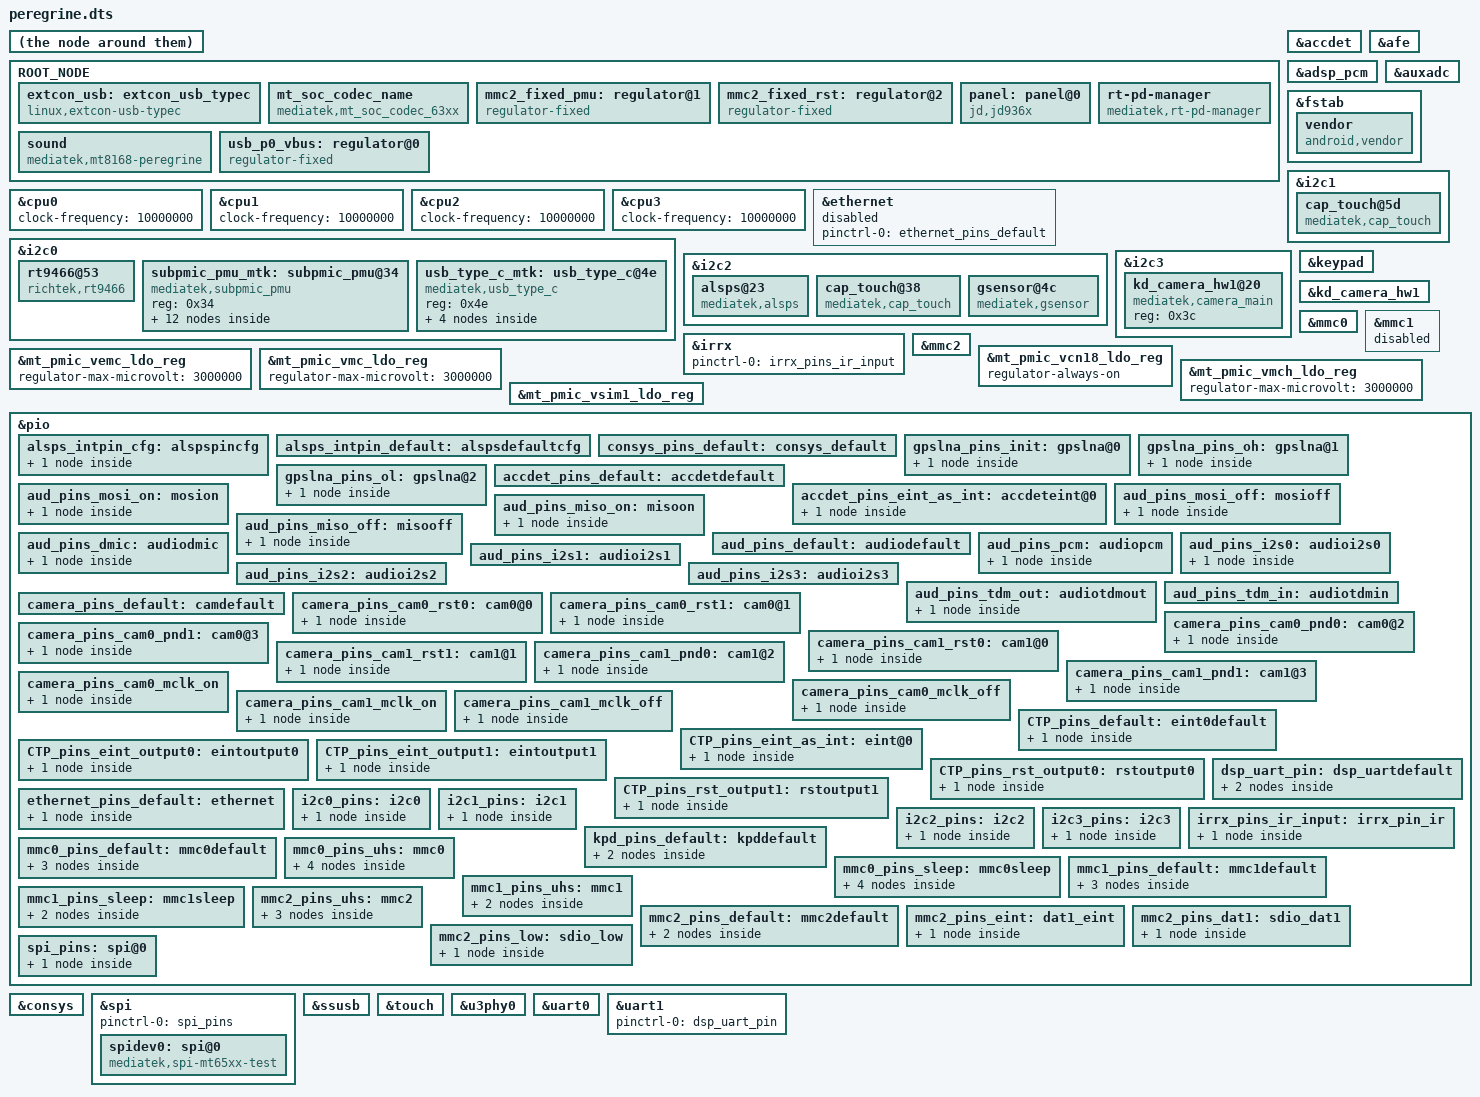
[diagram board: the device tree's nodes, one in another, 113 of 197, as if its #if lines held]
/*
 * Copyright (c) 2018 MediaTek Inc.
 *
 * This program is free software; you can redistribute it and/or modify
 * it under the terms of the GNU General Public License version 2 as
 * published by the Free Software Foundation.
 *
 * This program is distributed in the hope that it will be useful,
 * MERCHANTABILITY or FITNESS FOR A PARTICULAR PURPOSE.  See the
 * GNU General Public License for more details.
 */

#include <generated/autoconf.h>
/dts-v1/;

/plugin/;
#include <dt-bindings/clock/mt8168-clk.h>
#include <dt-bindings/interrupt-controller/irq.h>
#include <dt-bindings/interrupt-controller/arm-gic.h>
#include <dt-bindings/pinctrl/mt8168-pinfunc.h>
#include <dt-bindings/gpio/gpio.h>
#include <dt-bindings/phy/phy.h>
#define ROOT_NODE &odm

ROOT_NODE {
	extcon_usb: extcon_usb_typec {
		compatible = "linux,extcon-usb-typec";
	};

	mt_soc_codec_name: mt_soc_codec_name {
		compatible = "mediatek,mt_soc_codec_63xx";
		use_hp_depop_flow = <0>; /* select 1: use, 0: not use */
		use_ul_260k = <0>; /* select 1: use, 0: not use */
	};

	mmc2_fixed_pmu: regulator@1 {
		compatible = "regulator-fixed";
		regulator-name = "mmc2_pmu";
		regulator-min-microvolt = <3300000>;
		regulator-max-microvolt = <3300000>;
		gpio = <&pio 133 0>;
		enable-active-high;
	};

	mmc2_fixed_rst: regulator@2 {
		compatible = "regulator-fixed";
		regulator-name = "mmc2_rst";
		regulator-min-microvolt = <1800000>;
		regulator-max-microvolt = <1800000>;
		gpio = <&pio 143 0>;
		enable-active-high;
	};

	panel: panel@0 {
		compatible = "jd,jd936x";
		gpio_lcd_rst = <&pio 23 0>;
		gpio_bl_en = <&pio 79 0>;
	};

	rt-pd-manager {
		compatible = "mediatek,rt-pd-manager";
	};

	sound: sound {
		compatible = "mediatek,mt8168-peregrine";
		mediatek,platform = <&afe>;
		mediatek,adsp-platform = <&adsp_pcm>;
		pinctrl-names = "aud_mosi_on",
				"aud_mosi_off",
				"aud_miso_on",
				"aud_miso_off",
				"default",
				"aud_dmic",
				"aud_pcm",
				"aud_i2s0",
				"aud_i2s1",
				"aud_i2s2",
				"aud_i2s3",
				"aud_tdm_out",
				"aud_tdm_in";
		pinctrl-0 = <&aud_pins_mosi_on>;
		pinctrl-1 = <&aud_pins_mosi_off>;
		pinctrl-2 = <&aud_pins_miso_on>;
		pinctrl-3 = <&aud_pins_miso_off>;
		pinctrl-4 = <&aud_pins_default>;
		pinctrl-5 = <&aud_pins_dmic>;
		pinctrl-6 = <&aud_pins_pcm>;
		pinctrl-7 = <&aud_pins_i2s0>;
		pinctrl-8 = <&aud_pins_i2s1>;
		pinctrl-9 = <&aud_pins_i2s2>;
		pinctrl-10 = <&aud_pins_i2s3>;
		pinctrl-11 = <&aud_pins_tdm_out>;
		pinctrl-12 = <&aud_pins_tdm_in>;
		tab-spk-en-gpio = <&pio 3 0>;
		spkr-sel-gpio = <&pio 122 0>;
		mic-sel-gpio = <&pio 109 0>;
		status = "okay";
	};

	usb_p0_vbus: regulator@0 {
		compatible = "regulator-fixed";
		regulator-name = "vbus";
		regulator-min-microvolt = <5000000>;
		regulator-max-microvolt = <5000000>;
		gpio = <&pio 40 GPIO_ACTIVE_HIGH>;
		enable-active-high;
	};
};

&accdet {
	accdet-mic-vol = <6>;
	headset-mode-setting = <0x500 0x500 1 0x1f0 0x800 0x800 0x20 0x44>;
	accdet-plugout-debounce = <1>;
	accdet-mic-mode = <1>;
	headset-eint-level-pol = <8>;
	headset-three-key-threshold = <0 80 220 400>;
	headset-three-key-threshold-CDD = <0 121 192 600>;
	headset-four-key-threshold = <0 58 121 192 400>;
	pinctrl-names = "default", "state_eint_as_int";
	pinctrl-0 = <&accdet_pins_default>;
	pinctrl-1 = <&accdet_pins_eint_as_int>;
	status = "okay";
};

&afe {
	/* 0(I2S) 1(TDM) 2(I2S-32BITS) */
	mediatek,tdm-out-mode = <0>;
	/* 0(ONE_WIRE) 1(TWO_WIRE) */
	mediatek,dmic-two-wire-mode = <0>;
	/* 0(SEPARATE_CLK) 1(SHARE_CLK) */
	mediatek,i2s-clock-modes = <0 1>;
	status = "okay";
};

&adsp_pcm {
	status = "okay";
};

&auxadc {
	status = "okay";
};

&cpu0 {
	clock-frequency = <10000000>;
};

&cpu1 {
	clock-frequency = <10000000>;
};

&cpu2 {
	clock-frequency = <10000000>;
};

&cpu3 {
	clock-frequency = <10000000>;
};

&ethernet {
	status = "disabled";
	pinctrl-names = "default";
	pinctrl-0 = <&ethernet_pins_default>;
};

&fstab {
	vendor {
		compatible = "android,vendor";
		dev = "/dev/block/platform/soc/11230000.mmc/by-name/vendor";
		type = "ext4";
		mnt_flags = "ro";
		fsmgr_flags = "wait,verify";
	};
};

&i2c0 {
	pinctrl-names = "default";
	pinctrl-0 = <&i2c0_pins>;
	clock-frequency = <100000>;
	status = "okay";
	id = <0>;
	rt9466@53 {
		compatible = "richtek,rt9466";
		reg = <0x53>;
		/* rt,ceb_gpio_num = <160>; */
		interrupt-parent = <&pio>;
		interrupts = <124 IRQ_TYPE_EDGE_FALLING>;
		rt,intr_gpio = <&pio 10 0x0>;
		rt-interrupt-names = "wdtmri", "chg_mivr", "chg_aiclmeasi",
			"chg_statci", "chg_ieoci", "pwr_rdy";
		status = "okay";
		/*
		 * Charger name
		 * Main charger: primary_chg
		 * Slave charger: secondary_chg
		 */
		charger_name = "primary_chg";
		ichg = <2000000>; /* uA */
		aicr = <500000>;  /* uA */
		mivr = <4400000>; /* uV */
		cv = <4350000>;   /* uV */
		ieoc = <250000>;  /* uA */
		safety_timer = <12>;  /* hour */
		ircmp_resistor = <80000>; /* uohm */
		ircmp_vclamp = <96000>;  /* uV */
		en_te;
		/* en_wdt; */ /* remove it to support remote OTG wakeup */
		/* en_jeita; */
		/* en_irq_pulse; */
		/* ceb_invert; */
	};
	subpmic_pmu_mtk:subpmic_pmu@34 {
		compatible = "mediatek,subpmic_pmu";
		reg = <0x34>;
		status = "okay";
		mt6370_pmu: mt6370_pmu_dts {
			interrupt-controller;
			#interrupt-cells = <1>;
			interrupt-parent = <&pio>;
			interrupts = <12 IRQ_TYPE_EDGE_FALLING>;
			/* direct defined GPIO num */
			mt6370,intr_gpio_num = <12>;
			mt6370,intr_gpio = <&pio 12 0x0>; /* GPIO */
			core {
				compatible = "mediatek,mt6370_pmu_core";
				interrupt-names = "otp", "vdda_ovp", "vdda_uv";
				/* i2c safe timer reset function */
				//i2cstmr_rst_en;
				/* 0: 0.5s, 1: 0.75s, 2: 1s, 3: 2s */
				i2cstmr_rst_tmr = <0>;
				mrstb_en; /* external reset pin enable */
				/*
				 * 0: 0.75ms, 1: 1ms, 2: 1.25ms, 3: 1.5ms
				 * 4: 1.75ms, 5: 2ms, 6: 2.25ms, 7: 2.5ms
				 */
				mrstb_tmr = <3>;
				/* 0: disable, 1: 250ms, 2: 500ms, 3: 1s */
				int_wdt = <0>;
				/*
				 * interrupt deglitch,
				 * 0: 1ms, 1: 2ms, 2: 5ms, 3: 10ms
				 */
				int_deg = <0>;
			};
			charger {
				compatible = "mediatek,mt6370_pmu_charger";
				interrupt-names = "chg_mivr",
						  "chg_aiclmeasi",
						  "attachi",
						  "ovpctrl_uvp_d_evt",
						  "chg_wdtmri",
						  "chg_vbusov",
					"chg_tmri", "chg_treg";
				charger_name = "primary_chg";
				load_switch_name = "primary_load_switch";
				ichg = <2000000>;	/* uA */
				aicr = <500000>;	/* uA */
				mivr = <4400000>;	/* uV */
				cv = <4350000>;		/* uA */
				ieoc = <150000>;	/* uA */
				safety_timer = <12>;	/* hour */
				dc_wdt = <4000000>;	/* us */
				ircmp_resistor = <25000>;	/* uohm */
				ircmp_vclamp = <32000>;		/* uV */
				enable_te;
				enable_wdt;
				/* enable_polling; */
				/* is this charger needs polling */
				/* with it: do post aicl measure */
				post_aicl;
			};
			mt6370_pmu_fled1 {
				compatible = "mediatek,mt6370_pmu_fled1";
				interrupt-names = "fled_lvf", "fled2_short",
						  "fled1_short";
				fled_enable = <1>;
				torch_cur = <300000>;  /* 25000 ~ 400000 uA */
				strobe_cur = <1200000>;
				/* 25000  ~ 750000  uA : 6250  uA/step */
				/* 750000 ~ 1500000 uA : 12500 uA/step */
				strobe_timeout = <2400>; /* 64 ~ 2432 ms */
			};
			mt6370_pmu_fled2 {
				compatible = "mediatek,mt6370_pmu_fled2";
				fled_enable = <1>;
				torch_cur = <200000>;
				strobe_cur = <1000000>;
				strobe_timeout = <1200>;
			};
			ldo {
				compatible = "mediatek,mt6370_pmu_ldo";
				interrupt-names = "ldo_oc";
				/*
				 * 0: floating ;
				 * 1: discharge to ground for off mode
				 */
				ldo_oms = <1>;
				/*
				 * 0:  1 step/16us;
				 * 1 : 2 steps/16us;
				 * 2: 4 steps/16us;
				 * 3: 8steps/16us
				 * // ldo_vrc = <0>;
				 * to assign this a value
				 * will also set en_vrc = 1
				 */

				/* 0 : disable; 1: 10 us; 2: 20 us; 3: 40 us */
				ldo_vrc_lt = <1>;
				mt6370_ldo {
					/* change name by yourself */
					regulator-name = "irtx_ldo";
					regulator-min-microvolt = <1600000>;
					/* max == min then apply_uV = 1 */
					regulator-max-microvolt = <4000000>;
					/*
					 * regulator-microvolt-offset = < 0>;
					 * optional
					 * regulator-boot-on = "yes";
					 * optional, exist = enabled
					 * regulator-always-on = "yes";
					 * optional, exist = enabled
					 * regulator-ramp-delay = <100>;
					 * optional
					 */
				};
			};
			rgbled {
				compatible = "mediatek,mt6370_pmu_rgbled";
				interrupt-names = "isink4_short",
						  "isink3_short",
						  "isink2_short",
						  "isink1_short",
						  "isink4_open",
						  "isink3_open",
						  "isink2_open",
						  "isink1_open";
				/* name cnt must be 4 */
				mt,led_name = "mt6370_pmu_led1",
					      "mt6370_pmu_led2",
					      "mt6370_pmu_led3",
					      "mt6370_pmu_led4";
				/*
				 * trigger cnt must be 4,
				 * mode can be selected as
				 * cc_mode -> const current mode
				 * pwm_mode -> pwm dimming mode
				 * breath_mode -> as the name
				 */
				mt,led_default_trigger = "cc_mode", "cc_mode",
							 "cc_mode", "none";
			};
			bled {
				compatible = "mediatek,mt6370_pmu_bled";
				interrupt-names = "bled_ocp";
				mt,bled_name = "mt6370_pmu_bled";
				//mt,ext_en_pin;
				/* bit 0 1 2 3 -> chan 1 2 3 4 */
				mt,chan_en  = <0xf>;
				mt,map_linear;
				/* 0 17v, 1 21v, 2 25v, 3 29v */
				mt,bl_ovp_level = <3>;
				/* 0 900mA, 1 1200mA, 2 1500mA, 3 1800mA */
				mt,bl_ocp_level = <2>;
				mt,use_pwm;
				/* 0 1MHz, 1 4MHz, 2 or 3 24mHz */
				mt,pwm_fsample = <2>;
				/* 0 no filter, 1 100ns, 2 160ns, 3 200ns */
				mt,pwm_deglitch = <1>;
				mt,pwm_hys_en = <1>; /* PWM Input Hysteresis */
				mt,pwm_hys = <0>; /* 0: 1 bit, 1: 2 bit */
						  /* 2: 4 bit, 3: 6 bit */
				/*
				 * 0 disable avg, 1 avg 2 cycle,
				 * 2 avg 4 cycle, 3 avg 8 cycle,
				 * 4 avg 16 cycle, 5 avg 32 cycle
				 */
				mt,pwm_avg_cycle = <0>;
				/*
				 * 0, 500us, 750us, 1ms, 2ms, 5ms, 10ms, 20ms
				 * 50ms, 100ms, 250ms, 800ms, 1s, 2s, 4s, 8s
				 */
				mt,bled_ramptime = <3>;
				/* 0, 500us, 750us, 1ms, 2ms, 5ms */
				mt,bled_flash_ramp = <1>;
				/*
				 * we have 11 bit resolution,
				 * quantize in driver
				 * maximum 2047
				 */
				mt,max_bled_brightness = <512>;
			};
			dsv {
				compatible = "mediatek,mt6370_pmu_dsv";
				interrupt-names = "dsv_vneg_ocp",
						  "dsv_vpos_ocp",
						  "dsv_bst_ocp",
						  "dsv_vneg_scp",
						  "dsv_vpos_scp";
				/* 0 = i2c ctrl; 1 = ext pin */
				db_ext_en = <0>;
				/*
				 * 1 = prevent from voltage drop
				 * when db is restart
				 */
				db_periodic_fix = <0>;
				/*
				 * 0 => VOS & VNEG are ctrled by
				 * DB_ENP & DB_ENN;
				 * 1 : single pin ctrl
				 */
				db_single_pin = <0>;
				/*
				 * 0 = 20Hz ;
				 * 1 = 33Hz; valid if db_period_mode = 1
				 */
				db_freq_pm = <0>;
				/*
				 * 0 = always on if DB is enabled;
				 * 1 = DB period mode
				 */
				db_periodic_mode = <0>;
				/*
				 * 0 = close loop, wait 80%; 1 = open loop,
				 * go after soft-start dimming
				 */
				db_startup = <0>;
				/*
				 * 1 = DB VNEG discharge 20ms when shutdown;
				 * 0 = disable
				 */
				db_vneg_20ms = <1>;
				/*
				 * 1 = Discharge VNEG when turn off;
				 * 0 = disable
				 */
				db_vneg_disc = <0>;
				/*
				 * 1 = DB VPOS discharge 20ms when shutdown;
				 * 0 = disable
				 */
				db_vpos_20ms = <1>;
				/*
				 * 1 = Discharge VPOS when turn off;
				 * 0 = disable
				 */
				db_vpos_disc = <1>;
				/*
				 * 0 = no constraint;
				 * 1 = 0 ms;
				 * 2 = 1 ms;
				 * 3 = 4 ms
				 */
				db_delay = <3>;
				db_vbst  = <5700>; /* mV */
				/*
				 * 0 : 8.46 V/ms;
				 * 1 : 5.79 V/ms;
				 * 2: 3.87 V/ms;
				 * 3: 2.97V/ms
				 */
				db_vpos_slew = <1>;
				/*
				 * 0: -9.24V/ms;
				 * 1: -5.97V/ms;
				 * 2: -4.82V/ms;
				 * 3: -3.07V/ms
				 */
				db_vneg_slew = <1>;
				mt6370_dsvp {
					/* change name by yourself */
					regulator-name = "dsv_pos";
					regulator-min-microvolt = <5000000>;
					/* max == min then apply_uV = 1 */
					regulator-max-microvolt = <5000000>;
					/* regulator-microvolt-offset = < 0>;
					 * optional
					 * regulator-boot-on = "yes";
					 * optional, exist = enabled
					 * regulator-always-on = "yes";
					 * optional, exist = enabled
					 * regulator-ramp-delay = <100>;
					 * optional
					 */
				};
				mt6370_dsvn {
					/* change name by yourself */
					regulator-name = "dsv_neg";
					regulator-min-microvolt = <5000000>;
					/* max == min then apply_uV = 1 */
					regulator-max-microvolt = <5000000>;
					/*
					 * regulator-microvolt-offset = < 0>;
					 * optional
					 * regulator-boot-on = "yes";
					 * optional, exist = enabled
					 * regulator-always-on = "yes";
					 * optional, exist = enabled
					 * regulator-ramp-delay = <100>;
					 * optional
					 */
				};
			};
		};
	};
	usb_type_c_mtk:usb_type_c@4e {
		compatible = "mediatek,usb_type_c";
		reg = <0x4e>;
		status = "okay";
		mt6370_typec: type_c_port0 {
			/* 0: dfp/ufp, 1: dfp, 2: ufp */
			tcpc-dual,supported_modes = <0>;
			/* tcpc_device's name */
			mt-tcpc,name = "type_c_port0";
			/* 0: SNK Only, 1: SRC Only, 2: DRP,
			 * 3: Try.SRC, 4: Try.SNK
			 */
			mt-tcpc,role_def = <4>;
			/* 0: Default, 1: 1.5, 2: 3.0 */
			mt-tcpc,rp_level = <0>;
			/* 0: Never, 1: Always, 2: EMarkOnly, 3: StartOnly */
			mt-tcpc,vconn_supply  = <1>;
#if (CONFIG_MTK_GAUGE_VERSION == 30)
			/* the number of notifier supply */
			mt-tcpc,notifier_supply_num = <3>;
#else
			/* the number of notifier supply */
			mt-tcpc,notifier_supply_num = <2>;
#endif
			interrupt-parent = <&pio>;
			interrupts = <13 IRQ_TYPE_EDGE_FALLING>;
			mt6370pd,intr_gpio = <&pio 13 0x0>;
			mt6370pd,intr_gpio_num = <13>;

			pd-data {
				pd,vid = <0x29cf>;
				pd,pid = <0x5081>;
				pd,source-cap-ext = <0x171129cf 0x00000000
						     0x00000102 0x00000000
						     0x00000000 0x02000000>;
				pd,mfrs = "RichtekTCPC";

				/*
				 * VSAFE5V = 0, MAX_POWER = 1, CUSTOM = 2,
				 * MAX_POWER_LV = 0x21, MAX_POWER_LVIC = 0x31
				 * MAX_POWER_HV = 0x41, MAX_POWER_HVIC = 0x51
				 */
				pd,charging_policy= <0x21>;

				/*
				 * Fixed 5V, 500 mA <0x00019032>
				 * Fixed 5V, 1A <0x00019064>
				 * Fixed 5V, 2A <0x000190c8>
				 * Fixed 5V, 3A <0x0001912c>
				 * Fixed 9V, 500 mA <0x0002d032>
				 * Fixed 9V, 1A <0x0002d064>
				 * Fixed 9V, 2A <0x0002d0c8>
				 * Fixed 9V, 3A <0x0002d12c>
				 * Variable 5-9V, 1A <0x8642d064>
				 * Variable 5-9V, 2A <0x8642d0c8>
				 * Variable 5-9V, 3A <0x8642d12c>
				 * PPS 3V~5.9V, 3A <0xC0761E3C>
				 */
				pd,source-pdo-size = <1>;
				pd,source-pdo-data = <0x00019032>;
				pd,sink-pdo-size = <2>;
				pd,sink-pdo-data = <0x000190c8 0xC0761E3C>;

				/*
				 * No DP, host + device
				 *	pd,id-vdo-size = <3>;
				 *	pd,id-vdo-data = <0xd10029cf
				 *			  0x0
				 *			  0x00010000>;
				 * With DP
				 *	pd,id-vdo-size = <4>;
				 *	pd,id-vdo-data = <0xed0029cf
				 *			  0x0
				 *			  0x00010000
				 *			  0x11000001>;
				 */

				pd,id-vdo-size = <3>;
				pd,id-vdo-data = <0xd10029cf 0x00000000
						  0x00010000>;

				bat,nr = <1>;
				pd,country_nr = <0>;

				bat-info0 {
					bat,vid = <0x29cf>;
					bat,pid = <0x1711>;
					bat,mfrs = "bat1";
					bat,design_cap = <3000>;
				};

				//bat-info1 {
				//	bat,vid = <0x8abc>;
				//	bat,pid = <0x5234>;
				//	bat,mfrs = "bat2";
				//	bat,design_cap = <4000>;
				//};

				//country0 {
				//	pd,country_code = <0x5457>;
				//	pd,country_len = <2>; /* max len = 26 */
				//	pd,country_data = <0xff 0xff>;
				//};

				//country1 {
				//	pd,country_code = <0x5553>;
				//	pd,country_len = <3>; /* max len = 26 */
				//	pd,country_data = <0xf1 0xf2 0xf3>;
				//};
			};

			dpm_caps {
				local_dr_power;
				local_dr_data;
				//local_ext_power;
				local_usb_comm;
				//local_usb_suspend;
				//local_high_cap;
				//local_give_back;
				local_no_suspend;
				local_vconn_supply;

				//attemp_discover_cable_dfp;
				attemp_enter_dp_mode;
				attemp_discover_cable;
				attemp_discover_id;
				/* 0: disable, 1: prefer_snk, 2: prefer_src */
				pr_check = <0>;
				//pr_reject_as_source;
				//pr_reject_as_sink;
				pr_check_gp_source;
				//pr_check_gp_sink;

				/* 0: disable, 1: prefer_ufp, 2: prefer_dfp */
				dr_check = <0>;
				//dr_reject_as_dfp;
				//dr_reject_as_ufp;
			};
		};
	};
};

&i2c1 {
	pinctrl-names = "default";
	pinctrl-0 = <&i2c1_pins>;
	clock-frequency = <100000>;
	status = "okay";

	cap_touch@5d {
		compatible = "mediatek,cap_touch";
		reg = <0x5d>;
		interrupt-parent = <&pio>;
		interrupts = <5 IRQ_TYPE_EDGE_FALLING>;
		int-gpio = <&pio 5 0>;
		rst-gpio = <&pio 4 0>;
	};
};

&i2c2 {
	pinctrl-names = "default";
	pinctrl-0 = <&i2c2_pins>;
	clock-frequency = <100000>;
	status = "okay";

	alsps@23 {
		compatible = "mediatek,alsps";
		reg = <0x23>;
		interrupt-parent = <&pio>;
		interrupts = <10 IRQ_TYPE_LEVEL_LOW>;
		debounce = <10 0>;
		pinctrl-names = "pin_default", "pin_cfg";
		pinctrl-0 = <&alsps_intpin_default>;
		pinctrl-1 = <&alsps_intpin_cfg>;
		status = "okay";
		/* customization */
		i2c_num = <2>;
		i2c_addr = <0x23 0x0 0x0 0x00>;
		polling_mode_ps = <0>;
		polling_mode_als = <1>;
		power_id = <0xffff>;
		power_vol = <0>;
		als_level = <0 1 1 7 15 15 100 1000 2000 3000
			     6000 10000 14000 18000 20000>;
		als_value = <40 40 90 90 160 160 225 320 640
			     1280 1280 2600 2600 2600 10240 10240>;
		ps_threshold_high = <900>;
		ps_threshold_low = <600>;
		is_batch_supported_ps = <0>;
		is_batch_supported_als = <0>;
	};

	cap_touch@38 {
		compatible = "mediatek,cap_touch";
		reg = <0x38>;
		interrupt-parent = <&pio>;
		interrupts = <17 IRQ_TYPE_LEVEL_LOW>;
		int-gpio = <&pio 17 0>;
		rst-gpio = <&pio 16 0>;
	};

	gsensor@4c {
		compatible = "mediatek,gsensor";
		reg = <0x4c>;
		status = "okay";
		i2c_num = <2>;
		i2c_addr = <0x4c 0 0 0>;
		direction = <4>;
		power_id = <0xffff>;
		power_vol = <0>;
		firlen = <0>;
		is_batch_supported = <0>;
	};
};

&i2c3 {
	pinctrl-names = "default";
	pinctrl-0 = <&i2c3_pins>;
	clock-frequency = <400000>;
	status = "okay";

	kd_camera_hw1@20 {
		compatible = "mediatek,camera_main";
		reg = <0x3c>;
	};
};

&irrx {
	pinctrl-names = "default";
	pinctrl-0 = <&irrx_pins_ir_input>;
	status = "okay";
};

&keypad {
	pinctrl-names = "default";
	pinctrl-0 = <&kpd_pins_default>;
	status = "okay";
	mediatek,kpd-key-debounce = <1024>;
	mediatek,kpd-sw-pwrkey = <116>;
	mediatek,kpd-hw-pwrkey = <1>;
	mediatek,kpd-sw-rstkey  = <114>;
	mediatek,kpd-hw-rstkey = <3>;
	mediatek,kpd-use-extend-type = <0>;
	/*HW Keycode [0~3] -> Linux Keycode*/
	mediatek,kpd-hw-map-num = <72>;
	mediatek,kpd-hw-init-map =
			<115 0 0 0 0 0 0 0 0 0 0 0 0
			 0 0 0 0 0 0 0 0 0 0 0 0 0 0 0 0 0 0 0 0 0 0 0 0
			 0 0 0 0 0 0 0 0 0 0 0 0 0 0 0 0 0 0 0 0 0 0 0 0
			 0 0 0 0 0 0 0 0 0 0 0 >;
	mediatek,kpd-pwrkey-eint-gpio = <0>;
	mediatek,kpd-pwkey-gpio-din  = <0>;
	mediatek,kpd-hw-dl-key0 = <0>;
	mediatek,kpd-hw-dl-key1 = <3>;
	mediatek,kpd-hw-dl-key2 = <1>;
	mediatek,kpd-hw-recovery-key = <0>;
	mediatek,kpd-hw-factory-key  = <3>;
};


&kd_camera_hw1 {
	/* main cam power supply */
	vcama-supply = <&mt_pmic_vcama_ldo_reg>;         /* AVDD */
	vcamd-supply = <&mt_pmic_vcamd_ldo_reg>;         /* DVDD */
	vcamio-supply = <&mt_pmic_vcamio_ldo_reg>;       /* DOVDD */

	/* sub cam power supply */
	vcama_sub-supply = <&mt_pmic_vcama_ldo_reg>;         /* AVDD */
	vcamd_sub-supply = <&mt_pmic_vcamd_ldo_reg>;         /* DVDD */
	vcamio_sub-supply = <&mt_pmic_vcamio_ldo_reg>;       /* DOVDD */

	pinctrl-names = "default",
			"cam0_rst0", "cam0_rst1", "cam0_pnd0", "cam0_pnd1",
			"cam1_rst0", "cam1_rst1", "cam1_pnd0", "cam1_pnd1",
			"cam0_mclk_on", "cam0_mclk_off",
			"cam1_mclk_on", "cam1_mclk_off";

	pinctrl-0 = <&camera_pins_default>;
	pinctrl-1 = <&camera_pins_cam0_rst0>;
	pinctrl-2 = <&camera_pins_cam0_rst1>;
	pinctrl-3 = <&camera_pins_cam0_pnd0>;
	pinctrl-4 = <&camera_pins_cam0_pnd1>;
	pinctrl-5 = <&camera_pins_cam1_rst0>;
	pinctrl-6 = <&camera_pins_cam1_rst1>;
	pinctrl-7 = <&camera_pins_cam1_pnd0>;
	pinctrl-8 = <&camera_pins_cam1_pnd1>;
	pinctrl-9 = <&camera_pins_cam0_mclk_on>;
	pinctrl-10 = <&camera_pins_cam0_mclk_off>;
	pinctrl-11 = <&camera_pins_cam1_mclk_on>;
	pinctrl-12 = <&camera_pins_cam1_mclk_off>;

	status = "okay";
};

&mmc0 {
	status = "okay";
	pinctrl-names = "default", "state_uhs", "sleep";
	pinctrl-0 = <&mmc0_pins_default>;
	pinctrl-1 = <&mmc0_pins_uhs>;
	pinctrl-2 = <&mmc0_pins_sleep>;
	bus-width = <8>;
	max-frequency = <200000000>;
	cap-mmc-highspeed;
	mmc-hs200-1_8v;
	mmc-hs400-1_8v;
	cap-cqe;
	cap-cqe_dcmd;
	hs400-ds-delay = <0x12012>;
	vmmc-supply = <&mt_pmic_vemc_ldo_reg>;
	vqmmc-supply = <&mt_pmic_vio18_ldo_reg>;
	assigned-clocks = <&topckgen CLK_TOP_MSDC50_0_SEL>;
	assigned-clock-parents = <&topckgen CLK_TOP_MSDCPLL>;
	non-removable;
	no-sd;
	no-sdio;
};

&mmc1 {
	status = "disabled";
	pinctrl-names = "default", "state_uhs", "sleep";
	pinctrl-0 = <&mmc1_pins_default>;
	pinctrl-1 = <&mmc1_pins_uhs>;
	pinctrl-2 = <&mmc1_pins_sleep>;
	bus-width = <4>;
	max-frequency = <200000000>;
	cap-sd-highspeed;
	sd-uhs-sdr50;
	sd-uhs-sdr104;
	cd-gpios = <&pio 7 GPIO_ACTIVE_HIGH>;
	vmmc-supply = <&mt_pmic_vmch_ldo_reg>;
	vqmmc-supply = <&mt_pmic_vmc_ldo_reg>;
	no-mmc;
	no-sdio;
};

&mmc2 {
	status = "okay";
	pinctrl-names = "default", "state_uhs",	"state_eint",
			"state_dat1", "state_low";
	pinctrl-0 = <&mmc2_pins_default>;
	pinctrl-1 = <&mmc2_pins_uhs>;
	pinctrl-2 = <&mmc2_pins_eint>;
	pinctrl-3 = <&mmc2_pins_dat1>;
	pinctrl-4 = <&mmc2_pins_low>;
	eint-gpios = <&pio 83 0>;
	bus-width = <4>;
	max-frequency = <200000000>;
	cap-sd-highspeed;
	sd-uhs-sdr104;
	sd-uhs-sdr50;
	sd-uhs-sdr25;
	keep-power-in-suspend;
	enable-sdio-wakeup;
	cap-sdio-irq;
	no-mmc;
	no-sd;
	non-removable;
	vmmc-supply = <&mmc2_fixed_pmu>;
	vqmmc-supply = <&mmc2_fixed_rst>;
	assigned-clocks = <&topckgen CLK_TOP_MSDC50_2_SEL>;
	ssigned-clock-parents = <&topckgen CLK_TOP_MSDCPLL>;
};

&mt_pmic_vcn18_ldo_reg {
	regulator-always-on;
};

&mt_pmic_vemc_ldo_reg {
	regulator-max-microvolt = <3000000>;
};

&mt_pmic_vmc_ldo_reg {
	regulator-max-microvolt = <3000000>;
};

&mt_pmic_vmch_ldo_reg {
	regulator-max-microvolt = <3000000>;
};

&mt_pmic_vsim1_ldo_reg {
	regulator-min-microvolt = <1800000>;
	regulator-max-microvolt = <1800000>;
	regulator-boot-on;
};

/* CONSYS GPIO standardization */
&pio {
	alsps_intpin_cfg: alspspincfg {
		pins_cmd_dat {
			pinmux = <MT8168_PIN_10_GPIO10__FUNC_GPIO10>;
			slew-rate = <0>;
			bias-pull-up = <00>;
		};
	};
	alsps_intpin_default: alspsdefaultcfg {
	};
	consys_pins_default: consys_default {
	};
	gpslna_pins_init: gpslna@0 {
		pins_cmd_dat {
			pinmux = <MT8168_PIN_5_GPIO5__FUNC_GPIO5>;
			slew-rate = <0>;
			bias-disable;
			output-low;
		};
	};
	gpslna_pins_oh: gpslna@1 {
		pins_cmd_dat {
			pinmux = <MT8168_PIN_5_GPIO5__FUNC_GPIO5>;
			slew-rate = <1>;
			output-high;
		};
	};
	gpslna_pins_ol: gpslna@2 {
		pins_cmd_dat {
			pinmux = <MT8168_PIN_5_GPIO5__FUNC_GPIO5>;
			slew-rate = <1>;
			output-low;
		};
	};
};
&consys {
	pinctrl-names = "default", "gps_lna_state_init",
		"gps_lna_state_oh", "gps_lna_state_ol";
	pinctrl-0 = <&consys_pins_default>;
	pinctrl-1 = <&gpslna_pins_init>;
	pinctrl-2 = <&gpslna_pins_oh>;
	pinctrl-3 = <&gpslna_pins_ol>;
	status = "okay";
};
/* CONSYS end */

&pio {
	pinctrl-names = "default";

	accdet_pins_default: accdetdefault {
	};

	accdet_pins_eint_as_int: accdeteint@0 {
		pins_cmd_dat {
			pinmux = <MT8168_PIN_9_GPIO9__FUNC_GPIO9>;
			slew-rate = <0>;
			bias-disable;
		};
	};

	aud_pins_mosi_on: mosion {
		pins_cmd_dat {
		pinmux = <MT8168_PIN_49_AUD_CLK_MOSI__FUNC_AUD_CLK_MOSI>,
			 <MT8168_PIN_50_AUD_SYNC_MOSI__FUNC_AUD_SYNC_MOSI>,
			 <MT8168_PIN_51_AUD_DAT_MOSI0__FUNC_AUD_DAT_MOSI0>,
			 <MT8168_PIN_52_AUD_DAT_MOSI1__FUNC_AUD_DAT_MOSI1>;
		drive-strength = <MTK_DRIVE_6mA>;
		};
	};

	aud_pins_mosi_off: mosioff {
		pins_cmd_dat {
		pinmux = <MT8168_PIN_49_AUD_CLK_MOSI__FUNC_GPIO49>,
			 <MT8168_PIN_50_AUD_SYNC_MOSI__FUNC_GPIO50>,
			 <MT8168_PIN_51_AUD_DAT_MOSI0__FUNC_GPIO51>,
			 <MT8168_PIN_52_AUD_DAT_MOSI1__FUNC_GPIO52>;
		};
	};

	aud_pins_miso_on: misoon {
		pins_cmd_dat {
		pinmux = <MT8168_PIN_53_AUD_CLK_MISO__FUNC_AUD_CLK_MISO>,
			 <MT8168_PIN_54_AUD_SYNC_MISO__FUNC_AUD_SYNC_MISO>,
			 <MT8168_PIN_55_AUD_DAT_MISO0__FUNC_AUD_DAT_MISO0>,
			 <MT8168_PIN_56_AUD_DAT_MISO1__FUNC_AUD_DAT_MISO1>;
		drive-strength = <MTK_DRIVE_6mA>;
		};
	};

	aud_pins_miso_off: misooff {
		pins_cmd_dat {
		pinmux = <MT8168_PIN_53_AUD_CLK_MISO__FUNC_GPIO53>,
			 <MT8168_PIN_54_AUD_SYNC_MISO__FUNC_GPIO54>,
			 <MT8168_PIN_55_AUD_DAT_MISO0__FUNC_GPIO55>,
			 <MT8168_PIN_56_AUD_DAT_MISO1__FUNC_GPIO56>;
		};
	};

	aud_pins_default: audiodefault {
	};

	aud_pins_dmic: audiodmic {
		pins_cmd_dat {
		pinmux = <MT8168_PIN_117_DMIC0_CLK__FUNC_DMIC0_CLK>,
			 <MT8168_PIN_118_DMIC0_DAT0__FUNC_DMIC0_DAT0>,
			 <MT8168_PIN_120_DMIC1_CLK__FUNC_DMIC1_CLK>,
			 <MT8168_PIN_121_DMIC1_DAT0__FUNC_DMIC1_DAT0>,
			 <MT8168_PIN_123_DMIC2_CLK__FUNC_DMIC2_CLK>,
			 <MT8168_PIN_124_DMIC2_DAT0__FUNC_DMIC2_DAT0>,
			 <MT8168_PIN_126_DMIC3_CLK__FUNC_DMIC3_CLK>,
			 <MT8168_PIN_127_DMIC3_DAT0__FUNC_DMIC3_DAT0>;
		};
	};

	aud_pins_pcm: audiopcm {
		pins_cmd_dat {
		pinmux = <MT8168_PIN_110_PCM_CLK__FUNC_PCM_CLK>,
			 <MT8168_PIN_111_PCM_SYNC__FUNC_PCM_SYNC>,
			 <MT8168_PIN_112_PCM_RX__FUNC_PCM_RX>,
			 <MT8168_PIN_113_PCM_TX__FUNC_PCM_TX>;
		};
	};

	aud_pins_i2s0: audioi2s0 {
		pins_cmd_dat {
		pinmux = <MT8168_PIN_67_CMPCLK__FUNC_I2S0_BCK>,
			 <MT8168_PIN_68_CMDAT0__FUNC_I2S0_LRCK>,
			 <MT8168_PIN_69_CMDAT1__FUNC_I2S0_MCK>,
			 <MT8168_PIN_70_CMDAT2__FUNC_I2S0_DI>,
			 <MT8168_PIN_75_CMDAT7__FUNC_I2S3_DO>;
		};
	};

	aud_pins_i2s1: audioi2s1 {
	};

	aud_pins_i2s2: audioi2s2 {
	};

	aud_pins_i2s3: audioi2s3 {
	};

	aud_pins_tdm_out: audiotdmout {
		pins_cmd_dat {
		pinmux = <MT8168_PIN_129_TDM_TX_BCK__FUNC_I2S3_BCK>,
			 <MT8168_PIN_130_TDM_TX_LRCK__FUNC_I2S3_LRCK>,
			 <MT8168_PIN_131_TDM_TX_MCK__FUNC_I2S3_MCK>,
			 <MT8168_PIN_132_TDM_TX_DATA0__FUNC_I2S3_DO>;
		};
	};

	aud_pins_tdm_in: audiotdmin {
	};

	camera_pins_default: camdefault {
	};

	camera_pins_cam0_rst0: cam0@0 {
		pins_cmd_dat {
			pinmux = <MT8168_PIN_107_NCEB0__FUNC_GPIO107>;
			slew-rate = <1>; /*direction 0:in, 1:out*/
			output-low;
		};
	};

	camera_pins_cam0_rst1: cam0@1 {
		pins_cmd_dat {
			pinmux = <MT8168_PIN_107_NCEB0__FUNC_GPIO107>;
			slew-rate = <1>;
			output-high;
		};
	};

	camera_pins_cam0_pnd0: cam0@2 {
		pins_cmd_dat {
			pinmux = <MT8168_PIN_106_NCEB1__FUNC_GPIO106>;
			slew-rate = <1>;
			output-low;
		};
	};

	camera_pins_cam0_pnd1: cam0@3 {
		pins_cmd_dat {
			pinmux = <MT8168_PIN_106_NCEB1__FUNC_GPIO106>;
			slew-rate = <1>;
			output-high;
		};
	};

	camera_pins_cam1_rst0: cam1@0 {
		pins_cmd_dat {
			pinmux = <MT8168_PIN_88_MSDC1_CLK__FUNC_GPIO88>;
			slew-rate = <1>; /*direction 0:in, 1:out*/
			output-low;
		};
	};

	camera_pins_cam1_rst1: cam1@1 {
		pins_cmd_dat {
			pinmux = <MT8168_PIN_88_MSDC1_CLK__FUNC_GPIO88>;
			slew-rate = <1>;
			output-high;
		};
	};

	camera_pins_cam1_pnd0: cam1@2 {
		pins_cmd_dat {
			pinmux = <MT8168_PIN_87_MSDC1_CMD__FUNC_GPIO87>;
			slew-rate = <1>;
			output-low;
		};
	};

	camera_pins_cam1_pnd1: cam1@3 {
		pins_cmd_dat {
			pinmux = <MT8168_PIN_87_MSDC1_CMD__FUNC_GPIO87>;
			slew-rate = <1>;
			output-high;
		};
	};

	camera_pins_cam0_mclk_on: camera_pins_cam0_mclk_on {
		pins_cmd_dat {
			pinmux = <MT8168_PIN_66_CMMCLK1__FUNC_CMMCLK1>;
		};
	};

	camera_pins_cam0_mclk_off: camera_pins_cam0_mclk_off {
		pins_cmd_dat {
			pinmux = <MT8168_PIN_66_CMMCLK1__FUNC_GPIO66>;
		};
	};

	camera_pins_cam1_mclk_on: camera_pins_cam1_mclk_on {
		pins_cmd_dat {
			pinmux = <MT8168_PIN_65_CMMCLK0__FUNC_CMMCLK0>;
		};
	};

	camera_pins_cam1_mclk_off: camera_pins_cam1_mclk_off {
		pins_cmd_dat {
			pinmux = <MT8168_PIN_65_CMMCLK0__FUNC_GPIO65>;
		};
	};

	CTP_pins_default: eint0default {
		pins_cmd_dat {
			pinmux = <MT8168_PIN_17_GPIO17__FUNC_GPIO17>;
			slew-rate = <0>;
			bias-disable;
		};
	};

	CTP_pins_eint_as_int: eint@0 {
		pins_cmd_dat {
			pinmux = <MT8168_PIN_17_GPIO17__FUNC_GPIO17>;
			slew-rate = <0>;
			bias-disable;
		};
	};

	CTP_pins_eint_output0: eintoutput0 {
		pins_cmd_dat {
			pinmux = <MT8168_PIN_17_GPIO17__FUNC_GPIO17>;
			slew-rate = <1>;
			output-low;
		};
	};

	CTP_pins_eint_output1: eintoutput1 {
		pins_cmd_dat {
			pinmux = <MT8168_PIN_17_GPIO17__FUNC_GPIO17>;
			slew-rate = <1>;
			output-high;
		};
	};

	CTP_pins_rst_output0: rstoutput0 {
		pins_cmd_dat {
			pinmux = <MT8168_PIN_16_GPIO16__FUNC_GPIO16>;
			slew-rate = <1>;
			output-low;
		};
	};

	CTP_pins_rst_output1: rstoutput1 {
		pins_cmd_dat {
			pinmux = <MT8168_PIN_16_GPIO16__FUNC_GPIO16>;
			slew-rate = <1>;
			output-high;
		};
	};

	dsp_uart_pin: dsp_uartdefault {
		pins_rx {
			pinmux = <MT8168_PIN_37_URXD1__FUNC_DSP_URXD0>;
			input-enable;
			bias-pull-up;
		};
		pins_tx {
			pinmux = <MT8168_PIN_38_UTXD1__FUNC_DSP_UTXD0>;
		};
	};

	ethernet_pins_default: ethernet {
		pins_ethernet {
			pinmux = <MT8168_PIN_0_GPIO0__FUNC_EXT_TXD0>,
				 <MT8168_PIN_1_GPIO1__FUNC_EXT_TXD1>,
				 <MT8168_PIN_2_GPIO2__FUNC_EXT_TXD2>,
				 <MT8168_PIN_3_GPIO3__FUNC_EXT_TXD3>,
				 <MT8168_PIN_4_GPIO4__FUNC_EXT_TXC>,
				 <MT8168_PIN_5_GPIO5__FUNC_EXT_RXER>,
				 <MT8168_PIN_6_GPIO6__FUNC_EXT_RXC>,
				 <MT8168_PIN_7_GPIO7__FUNC_EXT_RXDV>,
				 <MT8168_PIN_8_GPIO8__FUNC_EXT_RXD0>,
				 <MT8168_PIN_9_GPIO9__FUNC_EXT_RXD1>,
				 <MT8168_PIN_11_GPIO11__FUNC_EXT_RXD3>,
				 <MT8168_PIN_12_GPIO12__FUNC_EXT_TXEN>,
				 <MT8168_PIN_13_GPIO13__FUNC_EXT_COL>,
				 <MT8168_PIN_14_GPIO14__FUNC_EXT_MDIO>,
				 <MT8168_PIN_15_GPIO15__FUNC_EXT_MDC>;
		};
	};

	i2c0_pins: i2c0 {
		pins_bus {
			pinmux = <MT8168_PIN_57_SDA0__FUNC_SDA0_0>,
				 <MT8168_PIN_58_SCL0__FUNC_SCL0_0>;
			bias-disable;
		};
	};

	i2c1_pins: i2c1 {
		pins_bus {
			pinmux = <MT8168_PIN_59_SDA1__FUNC_SDA1_0>,
				 <MT8168_PIN_60_SCL1__FUNC_SCL1_0>;
			bias-disable;
		};
	};

	i2c2_pins: i2c2 {
		pins_bus {
			pinmux = <MT8168_PIN_61_SDA2__FUNC_SDA2_0>,
				 <MT8168_PIN_62_SCL2__FUNC_SCL2_0>;
			bias-disable;
		};
	};

	i2c3_pins: i2c3 {
		pins_bus {
			pinmux = <MT8168_PIN_63_SDA3__FUNC_SDA3_0>,
				 <MT8168_PIN_64_SCL3__FUNC_SCL3_0>;
			bias-disable;
		};
	};

	irrx_pins_ir_input: irrx_pin_ir {
		pins_cmd_dat {
			pinmux = <MT8168_PIN_15_GPIO15__FUNC_IRRX>;
			bias-disable;
		};
	};

	kpd_pins_default: kpddefault {
		pins_cols {
			pinmux = <MT8168_PIN_24_KPCOL0__FUNC_KPCOL0>,
				 <MT8168_PIN_25_KPCOL1__FUNC_KPCOL1>;
			input-enable;
			bias-pull-up = <MTK_PUPD_SET_R1R0_01>;
		};

		pins_rows {
			pinmux = <MT8168_PIN_22_KPROW0__FUNC_KPROW0>;
			output-low;
			bias-disable;
		};
	};

	mmc0_pins_default: mmc0default {
		pins_clk {
			pinmux = <MT8168_PIN_99_MSDC0_CLK__FUNC_MSDC0_CLK>;
			bias-pull-down;
		};

		pins_cmd_dat {
			pinmux = <MT8168_PIN_103_MSDC0_DAT0__FUNC_MSDC0_DAT0>,
				 <MT8168_PIN_102_MSDC0_DAT1__FUNC_MSDC0_DAT1>,
				 <MT8168_PIN_101_MSDC0_DAT2__FUNC_MSDC0_DAT2>,
				 <MT8168_PIN_100_MSDC0_DAT3__FUNC_MSDC0_DAT3>,
				 <MT8168_PIN_96_MSDC0_DAT4__FUNC_MSDC0_DAT4>,
				 <MT8168_PIN_95_MSDC0_DAT5__FUNC_MSDC0_DAT5>,
				 <MT8168_PIN_94_MSDC0_DAT6__FUNC_MSDC0_DAT6>,
				 <MT8168_PIN_93_MSDC0_DAT7__FUNC_MSDC0_DAT7>,
				 <MT8168_PIN_98_MSDC0_CMD__FUNC_MSDC0_CMD>;
			input-enable;
			bias-pull-up;
		};

		pins_rst {
			pinmux = <MT8168_PIN_97_MSDC0_RSTB__FUNC_MSDC0_RSTB>;
			bias-pull-up;
		};
	};

	mmc0_pins_uhs: mmc0 {
		pins_clk {
			pinmux = <MT8168_PIN_99_MSDC0_CLK__FUNC_MSDC0_CLK>;
			drive-strength = <MTK_DRIVE_6mA>;
			bias-pull-down = <MTK_PUPD_SET_R1R0_01>;
		};

		pins_cmd_dat {
			pinmux = <MT8168_PIN_103_MSDC0_DAT0__FUNC_MSDC0_DAT0>,
				 <MT8168_PIN_102_MSDC0_DAT1__FUNC_MSDC0_DAT1>,
				 <MT8168_PIN_101_MSDC0_DAT2__FUNC_MSDC0_DAT2>,
				 <MT8168_PIN_100_MSDC0_DAT3__FUNC_MSDC0_DAT3>,
				 <MT8168_PIN_96_MSDC0_DAT4__FUNC_MSDC0_DAT4>,
				 <MT8168_PIN_95_MSDC0_DAT5__FUNC_MSDC0_DAT5>,
				 <MT8168_PIN_94_MSDC0_DAT6__FUNC_MSDC0_DAT6>,
				 <MT8168_PIN_93_MSDC0_DAT7__FUNC_MSDC0_DAT7>,
				 <MT8168_PIN_98_MSDC0_CMD__FUNC_MSDC0_CMD>;
			input-enable;
			drive-strength = <MTK_DRIVE_6mA>;
			bias-pull-up = <MTK_PUPD_SET_R1R0_01>;
		};

		pins_ds {
			pinmux = <MT8168_PIN_104_MSDC0_DSL__FUNC_MSDC0_DSL>;
			drive-strength = <MTK_DRIVE_6mA>;
			bias-pull-down = <MTK_PUPD_SET_R1R0_10>;
			input-enable;
		};

		pins_rst {
			pinmux = <MT8168_PIN_97_MSDC0_RSTB__FUNC_MSDC0_RSTB>;
			bias-pull-up;
		};
	};

	mmc0_pins_sleep: mmc0sleep {
		pins_clk {
			pinmux = <MT8168_PIN_99_MSDC0_CLK__FUNC_MSDC0_CLK>;
			bias-disable;
			input-disable;
		};

		pins_cmd_dat {
			pinmux = <MT8168_PIN_103_MSDC0_DAT0__FUNC_MSDC0_DAT0>,
				 <MT8168_PIN_102_MSDC0_DAT1__FUNC_MSDC0_DAT1>,
				 <MT8168_PIN_101_MSDC0_DAT2__FUNC_MSDC0_DAT2>,
				 <MT8168_PIN_100_MSDC0_DAT3__FUNC_MSDC0_DAT3>,
				 <MT8168_PIN_96_MSDC0_DAT4__FUNC_MSDC0_DAT4>,
				 <MT8168_PIN_95_MSDC0_DAT5__FUNC_MSDC0_DAT5>,
				 <MT8168_PIN_94_MSDC0_DAT6__FUNC_MSDC0_DAT6>,
				 <MT8168_PIN_93_MSDC0_DAT7__FUNC_MSDC0_DAT7>,
				 <MT8168_PIN_98_MSDC0_CMD__FUNC_MSDC0_CMD>;
			bias-disable;
			input-disable;
		};

		pins_ds {
			pinmux = <MT8168_PIN_104_MSDC0_DSL__FUNC_MSDC0_DSL>;
			bias-disable;
			input-disable;
		};

		pins_rst {
			pinmux = <MT8168_PIN_97_MSDC0_RSTB__FUNC_MSDC0_RSTB>;
			bias-disable;
			input-disable;
		};
	};

	mmc1_pins_default: mmc1default {
		pins_clk {
			pinmux = <MT8168_PIN_88_MSDC1_CLK__FUNC_MSDC1_CLK>;
			drive-strength = <MTK_DRIVE_4mA>;
			bias-pull-down = <MTK_PUPD_SET_R1R0_10>;
		};

		pins_cmd_dat {
			pinmux = <MT8168_PIN_89_MSDC1_DAT0__FUNC_MSDC1_DAT0>,
				 <MT8168_PIN_90_MSDC1_DAT1__FUNC_MSDC1_DAT1>,
				 <MT8168_PIN_91_MSDC1_DAT2__FUNC_MSDC1_DAT2>,
				 <MT8168_PIN_92_MSDC1_DAT3__FUNC_MSDC1_DAT3>,
				 <MT8168_PIN_87_MSDC1_CMD__FUNC_MSDC1_CMD>;
			input-enable;
			drive-strength = <MTK_DRIVE_4mA>;
			bias-pull-up = <MTK_PUPD_SET_R1R0_01>;
		};

		pins_insert {
			pinmux = <MT8168_PIN_7_GPIO7__FUNC_GPIO7>;
			bias-pull-up;
		};
	};

	mmc1_pins_uhs: mmc1 {
		pins_clk {
			pinmux = <MT8168_PIN_88_MSDC1_CLK__FUNC_MSDC1_CLK>;
			drive-strength = <MTK_DRIVE_6mA>;
			bias-pull-down = <MTK_PUPD_SET_R1R0_10>;
		};

		pins_cmd_dat {
			pinmux = <MT8168_PIN_89_MSDC1_DAT0__FUNC_MSDC1_DAT0>,
				 <MT8168_PIN_90_MSDC1_DAT1__FUNC_MSDC1_DAT1>,
				 <MT8168_PIN_91_MSDC1_DAT2__FUNC_MSDC1_DAT2>,
				 <MT8168_PIN_92_MSDC1_DAT3__FUNC_MSDC1_DAT3>,
				 <MT8168_PIN_87_MSDC1_CMD__FUNC_MSDC1_CMD>;
			input-enable;
			drive-strength = <MTK_DRIVE_6mA>;
			bias-pull-up = <MTK_PUPD_SET_R1R0_01>;
		};
	};

	mmc1_pins_sleep: mmc1sleep {
		pins_clk {
			pinmux = <MT8168_PIN_88_MSDC1_CLK__FUNC_MSDC1_CLK>;
			bias-disable;
			input-disable;
		};

		pins_cmd_dat {
			pinmux = <MT8168_PIN_89_MSDC1_DAT0__FUNC_MSDC1_DAT0>,
				 <MT8168_PIN_90_MSDC1_DAT1__FUNC_MSDC1_DAT1>,
				 <MT8168_PIN_91_MSDC1_DAT2__FUNC_MSDC1_DAT2>,
				 <MT8168_PIN_92_MSDC1_DAT3__FUNC_MSDC1_DAT3>,
				 <MT8168_PIN_87_MSDC1_CMD__FUNC_MSDC1_CMD>;
			bias-disable;
			input-disable;
		};
	};

	mmc2_pins_default: mmc2default {
		pins_clk {
			pinmux = <MT8168_PIN_81_MSDC2_CLK__FUNC_MSDC2_CLK>;
			drive-strength = <MTK_DRIVE_4mA>;
			bias-pull-down = <MTK_PUPD_SET_R1R0_10>;
		};

		pins_cmd_dat {
			pinmux = <MT8168_PIN_82_MSDC2_DAT0__FUNC_MSDC2_DAT0>,
				 <MT8168_PIN_83_MSDC2_DAT1__FUNC_MSDC2_DAT1>,
				 <MT8168_PIN_84_MSDC2_DAT2__FUNC_MSDC2_DAT2>,
				 <MT8168_PIN_85_MSDC2_DAT3__FUNC_MSDC2_DAT3>,
				 <MT8168_PIN_80_MSDC2_CMD__FUNC_MSDC2_CMD>;
			input-enable;
			drive-strength = <MTK_DRIVE_4mA>;
			bias-pull-up = <MTK_PUPD_SET_R1R0_01>;
		};
	};

	mmc2_pins_uhs: mmc2 {
		pins_clk {
			pinmux = <MT8168_PIN_81_MSDC2_CLK__FUNC_MSDC2_CLK>;
			drive-strength = <MTK_DRIVE_8mA>;
			bias-pull-down = <MTK_PUPD_SET_R1R0_10>;
		};

		pins_cmd_dat {
			pinmux = <MT8168_PIN_82_MSDC2_DAT0__FUNC_MSDC2_DAT0>,
				 <MT8168_PIN_83_MSDC2_DAT1__FUNC_MSDC2_DAT1>,
				 <MT8168_PIN_84_MSDC2_DAT2__FUNC_MSDC2_DAT2>,
				 <MT8168_PIN_85_MSDC2_DAT3__FUNC_MSDC2_DAT3>,
				 <MT8168_PIN_80_MSDC2_CMD__FUNC_MSDC2_CMD>;
			input-enable;
			drive-strength = <MTK_DRIVE_8mA>;
			bias-pull-up = <MTK_PUPD_SET_R1R0_01>;
		};

		pins_ds {
			pinmux = <MT8168_PIN_86_MSDC2_DSL__FUNC_MSDC2_DSL>;
			drive-strength = <MTK_DRIVE_8mA>;
			bias-pull-down = <MTK_PUPD_SET_R1R0_10>;
		};
	};

	mmc2_pins_eint: dat1_eint {
		pins_dat1 {
			pinmux = <MT8168_PIN_83_MSDC2_DAT1__FUNC_GPIO83>;
			input-enable;
			bias-pull-up = <MTK_PUPD_SET_R1R0_01>;
		};
	};

	mmc2_pins_dat1: sdio_dat1 {
		pins_dat1 {
			pinmux = <MT8168_PIN_83_MSDC2_DAT1__FUNC_MSDC2_DAT1>;
			input-enable;
			drive-strength = <MTK_DRIVE_8mA>;
			bias-pull-up = <MTK_PUPD_SET_R1R0_01>;
		};
	};

	mmc2_pins_low: sdio_low {
		pins_low {
			pinmux = <MT8168_PIN_82_MSDC2_DAT0__FUNC_GPIO82>,
				 <MT8168_PIN_84_MSDC2_DAT2__FUNC_GPIO84>,
				 <MT8168_PIN_85_MSDC2_DAT3__FUNC_GPIO85>,
				 <MT8168_PIN_80_MSDC2_CMD__FUNC_GPIO80>,
				 <MT8168_PIN_86_MSDC2_DSL__FUNC_GPIO86>;
			input-disable;
			bias-disable;
		};
	};

	spi_pins: spi@0 {
		pins_spi {
			pinmux = <MT8168_PIN_26_SPI_CS__FUNC_SPI_CSB>,
				 <MT8168_PIN_27_SPI_CK__FUNC_SPI_CLK>,
				 <MT8168_PIN_28_SPI_MI__FUNC_SPI_MI>,
				 <MT8168_PIN_29_SPI_MO__FUNC_SPI_MO>;
			bias-disable;
		};
	};
};

&spi {
	pinctrl-names = "default";
	pinctrl-0 = <&spi_pins>;
	status = "okay";

	spidev0: spi@0 {
		compatible = "mediatek,spi-mt65xx-test";
		reg = <0>;
		spi-max-frequency = <1000000>;
	};
};

&ssusb {
	phys = <&u2port0 PHY_TYPE_USB2>,
	       <&u2port1 PHY_TYPE_USB2>;
	vusb33-supply = <&mt_pmic_vusb33_ldo_reg>;
	mediatek,use-typec;
	extcon = <&extcon_usb>;
	dr_mode = "otg";
	status="okay";
};

&touch {
	vtouch-supply = <&mt_pmic_vmch_ldo_reg>;
	tpd-resolution = <720 1280>;
	use-tpd-button = <0>;
	tpd-key-num = <3>;
	tpd-key-local= <139 172 158 0>;
	tpd-key-dim-local = <145 1330 120 100 360 1330 120
			100 600 1330 120 100 0 0 0 0>;
	tpd-max-touch-num = <5>;
	tpd-filter-enable = <1>;
	tpd-filter-pixel-density = <124>;
	tpd-filter-custom-prameters = <0 0 0 0 0 0 0 0 0 0 0 0>;
	tpd-filter-custom-speed = <0 0 0>;
	pinctrl-names = "default", "state_eint_as_int",
		"state_eint_output0", "state_eint_output1",
		"state_rst_output0", "state_rst_output1";
	pinctrl-0 = <&CTP_pins_default>;
	pinctrl-1 = <&CTP_pins_eint_as_int>;
	pinctrl-2 = <&CTP_pins_eint_output0>;
	pinctrl-3 = <&CTP_pins_eint_output1>;
	pinctrl-4 = <&CTP_pins_rst_output0>;
	pinctrl-5 = <&CTP_pins_rst_output1>;
	status = "okay";
};

&u3phy0 {
	status="okay";
};

&uart0 {
	status="okay";
};

&uart1 {
	pinctrl-names = "default";
	pinctrl-0 = <&dsp_uart_pin>;
	status="okay";
};
